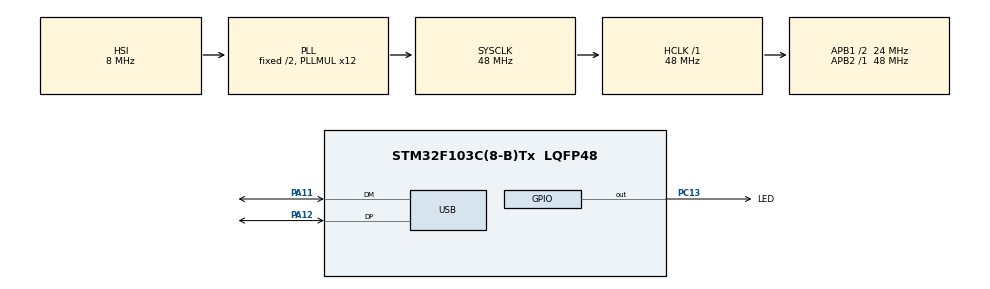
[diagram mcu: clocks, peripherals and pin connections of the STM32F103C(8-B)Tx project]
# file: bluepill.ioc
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FREERTOS.Tasks01=defaultTask,0,128,StartDefaultTask,Default,NULL
Mcu.Family=STM32F1
Mcu.Name=STM32F103C(8-B)Tx
Mcu.Package=LQFP48
NVIC.PriorityGroup=NVIC_PRIORITYGROUP_4
NVIC.USB_LP_CAN1_RX0_IRQn=true\:5\:0\:false\:false\:true\:true\:false
PA11.Mode=Device
PA11.Signal=USB_DM
PA12.Mode=Device
PA12.Signal=USB_DP
PA13.Mode=Serial_Wire
PA13.Signal=SYS_JTMS-SWDIO
PA14.Mode=Serial_Wire
PA14.Signal=SYS_JTCK-SWCLK
PC13-TAMPER-RTC.GPIO_Label=LED
PC13-TAMPER-RTC.Signal=GPIO_Output
ProjectManager.HeapSize=0x200
ProjectManager.StackSize=0x400
ProjectManager.TargetToolchain=Makefile
RCC.AHBFreq_Value=48000000
RCC.APB1CLKDivider=RCC_HCLK_DIV2
RCC.APB1Freq_Value=24000000
RCC.APB1TimFreq_Value=48000000
RCC.APB2Freq_Value=48000000
RCC.APB2TimFreq_Value=48000000
RCC.HCLKFreq_Value=48000000
RCC.PLLMUL=RCC_PLL_MUL12
RCC.PLLSource=RCC_PLLSOURCE_HSI_DIV2
RCC.PLLSourceVirtual=RCC_PLLSOURCE_HSI_DIV2
RCC.SYSCLKFreq_VALUE=48000000
RCC.SYSCLKSource=RCC_SYSCLKSOURCE_PLLCLK
RCC.USBFreq_Value=48000000
USB_DEVICE.CLASS_NAME_FS=HID
USB_DEVICE.VirtualMode=Hid
USB_DEVICE.VirtualModeFS=Hid_FS
VP_FREERTOS_VS_ENABLE.Mode=Enabled
VP_USB_DEVICE_VS_USB_DEVICE_HID_FS.Mode=HID_FS
board=custom

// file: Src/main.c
/* USER CODE BEGIN Header */
/**
  ******************************************************************************
  * @file           : main.c
  * @brief          : Main program body
  ******************************************************************************
  * This notice applies to any and all portions of this file
  * that are not between comment pairs USER CODE BEGIN and
  * USER CODE END. Other portions of this file, whether
  * inserted by the user or by software development tools
  * are owned by their respective copyright owners.
  *
  * Copyright (c) 2020 STMicroelectronics International N.V.
  * All rights reserved.
  *
  * Redistribution and use in source and binary forms, with or without
  * modification, are permitted, provided that the following conditions are met:
  *
  * 1. Redistribution of source code must retain the above copyright notice,
  *    this list of conditions and the following disclaimer.
  * 2. Redistributions in binary form must reproduce the above copyright notice,
  *    this list of conditions and the following disclaimer in the documentation
  *    and/or other materials provided with the distribution.
  * 3. Neither the name of STMicroelectronics nor the names of other
  *    contributors to this software may be used to endorse or promote products
  *    derived from this software without specific written permission.
  * 4. This software, including modifications and/or derivative works of this
  *    software, must execute solely and exclusively on microcontroller or
  *    microprocessor devices manufactured by or for STMicroelectronics.
  * 5. Redistribution and use of this software other than as permitted under
  *    this license is void and will automatically terminate your rights under
  *    this license.
  *
  * THIS SOFTWARE IS PROVIDED BY STMICROELECTRONICS AND CONTRIBUTORS "AS IS"
  * AND ANY EXPRESS, IMPLIED OR STATUTORY WARRANTIES, INCLUDING, BUT NOT
  * LIMITED TO, THE IMPLIED WARRANTIES OF MERCHANTABILITY, FITNESS FOR A
  * PARTICULAR PURPOSE AND NON-INFRINGEMENT OF THIRD PARTY INTELLECTUAL PROPERTY
  * RIGHTS ARE DISCLAIMED TO THE FULLEST EXTENT PERMITTED BY LAW. IN NO EVENT
  * SHALL STMICROELECTRONICS OR CONTRIBUTORS BE LIABLE FOR ANY DIRECT, INDIRECT,
  * INCIDENTAL, SPECIAL, EXEMPLARY, OR CONSEQUENTIAL DAMAGES (INCLUDING, BUT NOT
  * LIMITED TO, PROCUREMENT OF SUBSTITUTE GOODS OR SERVICES; LOSS OF USE, DATA,
  * OR PROFITS; OR BUSINESS INTERRUPTION) HOWEVER CAUSED AND ON ANY THEORY OF
  * LIABILITY, WHETHER IN CONTRACT, STRICT LIABILITY, OR TORT (INCLUDING
  * NEGLIGENCE OR OTHERWISE) ARISING IN ANY WAY OUT OF THE USE OF THIS SOFTWARE,
  * EVEN IF ADVISED OF THE POSSIBILITY OF SUCH DAMAGE.
  *
  ******************************************************************************
  */
/* USER CODE END Header */

#include "main.h"
#include "cmsis_os.h"
#include "usb_device.h"

/* USER CODE BEGIN PTD */
struct mouseHID_t {
    uint8_t buttons;
    uint8_t x;
    uint8_t y;
    uint8_t wheel;
};
struct keyboardHID_t {
	uint8_t id;
	uint8_t modifiers;
	uint8_t key1;
	uint8_t key2;
	uint8_t key3;
};
struct mediaHID_t {
	uint8_t id;
	uint8_t keys;
};
struct mouseHID_t mouseHID = { .x = 10 };
struct keyboardHID_t keyboardHID = { .id = 1 };
struct mediaHID_t mediaHID = { .id = 2 };
/* USER CODE END PTD */

osThreadId defaultTaskHandle;

void SystemClock_Config(void);
static void MX_GPIO_Init(void);
void StartDefaultTask(void const * argument);

int main(void)
{

  /* MCU Configuration--------------------------------------------------------*/

  /* Reset of all peripherals, Initializes the Flash interface and the Systick. */
  HAL_Init();

  /* Configure the system clock */
  SystemClock_Config();

  /* Initialize all configured peripherals */
  MX_GPIO_Init();

  /* Create the thread(s) */
  /* definition and creation of defaultTask */
  osThreadDef(defaultTask, StartDefaultTask, osPriorityNormal, 0, 128);
  defaultTaskHandle = osThreadCreate(osThread(defaultTask), NULL);

  /* Start scheduler */
  osKernelStart();

  /* We should never get here as control is now taken by the scheduler */

  /* Infinite loop */
  while (1)
  {

  }
}

void SystemClock_Config(void)
{
  RCC_OscInitTypeDef RCC_OscInitStruct = {0};
  RCC_ClkInitTypeDef RCC_ClkInitStruct = {0};
  RCC_PeriphCLKInitTypeDef PeriphClkInit = {0};

  /**Initializes the CPU, AHB and APB busses clocks
  */
  RCC_OscInitStruct.OscillatorType = RCC_OSCILLATORTYPE_HSI;
  RCC_OscInitStruct.HSIState = RCC_HSI_ON;
  RCC_OscInitStruct.HSICalibrationValue = RCC_HSICALIBRATION_DEFAULT;
  RCC_OscInitStruct.PLL.PLLState = RCC_PLL_ON;
  RCC_OscInitStruct.PLL.PLLSource = RCC_PLLSOURCE_HSI_DIV2;
  RCC_OscInitStruct.PLL.PLLMUL = RCC_PLL_MUL12;
  if (HAL_RCC_OscConfig(&RCC_OscInitStruct) != HAL_OK)
  {
    Error_Handler();
  }
  /**Initializes the CPU, AHB and APB busses clocks
  */
  RCC_ClkInitStruct.ClockType = RCC_CLOCKTYPE_HCLK|RCC_CLOCKTYPE_SYSCLK
                              |RCC_CLOCKTYPE_PCLK1|RCC_CLOCKTYPE_PCLK2;
  RCC_ClkInitStruct.SYSCLKSource = RCC_SYSCLKSOURCE_PLLCLK;
  RCC_ClkInitStruct.AHBCLKDivider = RCC_SYSCLK_DIV1;
  RCC_ClkInitStruct.APB1CLKDivider = RCC_HCLK_DIV2;
  RCC_ClkInitStruct.APB2CLKDivider = RCC_HCLK_DIV1;

  if (HAL_RCC_ClockConfig(&RCC_ClkInitStruct, FLASH_LATENCY_1) != HAL_OK)
  {
    Error_Handler();
  }
  PeriphClkInit.PeriphClockSelection = RCC_PERIPHCLK_USB;
  PeriphClkInit.UsbClockSelection = RCC_USBCLKSOURCE_PLL;
  if (HAL_RCCEx_PeriphCLKConfig(&PeriphClkInit) != HAL_OK)
  {
    Error_Handler();
  }
}

static void MX_GPIO_Init(void)
{
  GPIO_InitTypeDef GPIO_InitStruct = {0};

  /* GPIO Ports Clock Enable */
  __HAL_RCC_GPIOC_CLK_ENABLE();
  __HAL_RCC_GPIOA_CLK_ENABLE();

  /*Configure GPIO pin Output Level */
  HAL_GPIO_WritePin(LED_GPIO_Port, LED_Pin, GPIO_PIN_RESET);

  /*Configure GPIO pin : LED_Pin */
  GPIO_InitStruct.Pin = LED_Pin;
  GPIO_InitStruct.Mode = GPIO_MODE_OUTPUT_PP;
  GPIO_InitStruct.Pull = GPIO_NOPULL;
  GPIO_InitStruct.Speed = GPIO_SPEED_FREQ_LOW;
  HAL_GPIO_Init(LED_GPIO_Port, &GPIO_InitStruct);

}

void StartDefaultTask(void const * argument)
{
  /* init code for USB_DEVICE */
  MX_USB_DEVICE_Init();

  /* USER CODE BEGIN 5 */
  /* Infinite loop */
  for(;;)
  {
    osDelay(1000);
    keyboardHID.modifiers = (1 << 1);  // Left shift
    keyboardHID.key1 = 0x04; // Letter a
    USBD_HID_SendReport(&hUsbDeviceFS, (uint8_t*) &keyboardHID, sizeof(struct keyboardHID_t));
    HAL_Delay(30);
    keyboardHID.modifiers = 0;
    keyboardHID.key1 = 0;
    USBD_HID_SendReport(&hUsbDeviceFS, (uint8_t*) &keyboardHID, sizeof(struct keyboardHID_t));
  }
  /* USER CODE END 5 */
}

void Error_Handler(void)
{
}

/************************ (C) COPYRIGHT STMicroelectronics *****END OF FILE****/
